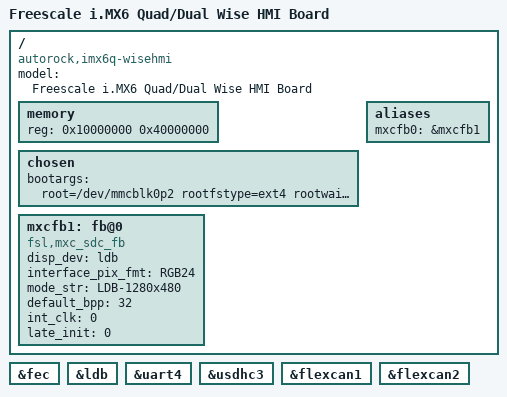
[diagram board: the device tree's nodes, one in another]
/*
 * Copyright (C) 2013 Freescale Semiconductor, Inc.
 *
 * This program is free software; you can redistribute it and/or modify
 * it under the terms of the GNU General Public License version 2 as
 * published by the Free Software Foundation.
 */

/dts-v1/;

#include "imx6q.dtsi"
#include "imx6qdl-wisehmi.dtsi"

/ {
	model = "Freescale i.MX6 Quad/Dual Wise HMI Board";
	compatible = "autorock,imx6q-wisehmi", "autorock,imx6qdl-wisehmi", "fsl,imx6q";

	memory {
		reg = <0x10000000 0x40000000>;
	};

	chosen {
        bootargs = "root=/dev/mmcblk0p2 rootfstype=ext4 rootwait rw console=ttymxc3,115200n8 lpj=7905280";
    };

	aliases {
		mxcfb0 = &mxcfb1;
	};

	mxcfb1: fb@0 {
		compatible = "fsl,mxc_sdc_fb";
		disp_dev = "ldb";
		interface_pix_fmt = "RGB24";
		mode_str ="LDB-1280x480";
		default_bpp = <32>;
		int_clk = <0>;
		late_init = <0>;
		status = "okay";
	};
};

&fec {
	status = "okay";
};

&ldb {
	status = "okay";
};

&uart4 {
	status = "okay";
};

&usdhc3 {
	status = "okay";
};

&flexcan1 {
	status = "okay";
};

&flexcan2 {
	status = "okay";
};

